VERSION ""

NS_ :

BS_:

BU_: BackLightLeft BackLightRight PDC KeylessEntry ZoneControllerRear

BO_ 768 AmbientLights: 6 ZoneController
 SG_ AmbientLightsOn : 0|1@1+ (1,0) [0|1] "" AmbientLights

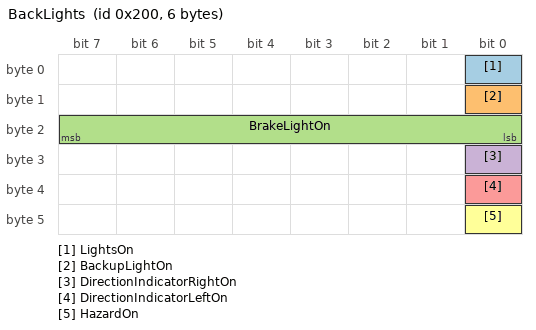
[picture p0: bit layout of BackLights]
BO_ 512 BackLights: 6 ZoneControllerRear
 SG_ LightsOn : 0|1@1+ (1,0) [0|1] "" BackLightLeft,BackLightRight
 SG_ BackupLightOn : 8|1@1+ (1,0) [0|1] "" BackLightLeft,BackLightRight
 SG_ BrakeLightOn : 16|8@1+ (1,0) [0|255] "" BackLightLeft,BackLightRight
 SG_ DirectionIndicatorRightOn : 24|1@1+ (1,0) [0|1] "" BackLightRight
 SG_ DirectionIndicatorLeftOn : 32|1@1+ (1,0) [0|1] "" BackLightLeft
 SG_ HazardOn : 40|1@1+ (1,0) [0|1] "" BackLightLeft,BackLightRight

BO_ 113 PDCSensor: 2 PDC
 SG_ PdcDistance : 0|8@1+ (1,0) [0|255] "" ZoneControllerRear

BO_ 112 PDCEnable: 2 ZoneControllerRear
 SG_ PdcActive : 0|1@1+ (1,0) [0|1] "" PDC

VAL_ 768 AmbientLightsOn 0 "OFF" 1 "ON";

VAL_ 512 LightsOn 0 "OFF" 1 "ON";
VAL_ 512 BackupLightOn 0 "OFF" 1 "ON";
VAL_ 512 BrakeLightOn 0 "OFF" 1 "ON" 2 "FLASH";
VAL_ 512 DirectionIndicatorRightOn 0 "OFF" 1 "ON";
VAL_ 512 DirectionIndicatorLeftOn 0 "OFF" 1 "ON";
VAL_ 512 HazardOn 0 "OFF" 1 "ON";

VAL_ 112 PdcActive 0 "INACTIVE" 1 "ACTIVE";
